# STM32H745_CM7 register map
File version: 2.5
CPU: CM7 r0p1, little endian, MPU, FPU, 4 interrupt priority bits
Registers are 32-bit, read-write, reset 0x0 unless marked. A register's access mark holds for its fields unless they carry their own. Offsets are from the block's base; [hi:lo] are bit positions; {n}, {i} and the like mark numbered series; 'fields as' and 'values as' point back to an identical list.

## BDMA
Base 0x58025400
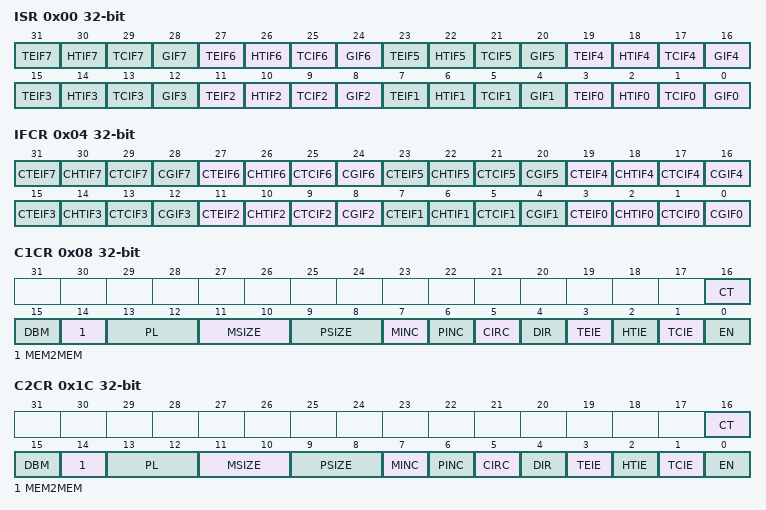
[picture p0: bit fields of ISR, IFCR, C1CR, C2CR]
0x00 ISR ro — DMA interrupt status register
  [4n+3] TEIF{n} (n=0..7) — Channel x transfer error flag (x = 1..8) This bit is set by hardware. It is cleared by software writing 1 to the corresponding bit in the DMA_IFCR register.
  [4n+2] HTIF{n} (n=0..7) — Channel x half transfer flag (x = 1..8) This bit is set by hardware. It is cleared by software writing 1 to the corresponding bit in the DMA_IFCR register.
  [4n+1] TCIF{n} (n=0..7) — Channel x transfer complete flag (x = 1..8) This bit is set by hardware. It is cleared by software writing 1 to the corresponding bit in the DMA_IFCR register.
  [4n] GIF{n} (n=0..7) — Channel x global interrupt flag (x = 1..8) This bit is set by hardware. It is cleared by software writing 1 to the corresponding bit in the DMA_IFCR register.
0x04 IFCR wo — DMA interrupt flag clear register
  [4n+3] CTEIF{n} (n=0..7) — Channel x transfer error clear This bit is set and cleared by software.
  [4n+2] CHTIF{n} (n=0..7) — Channel x half transfer clear This bit is set and cleared by software.
  [4n+1] CTCIF{n} (n=0..7) — Channel x transfer complete clear This bit is set and cleared by software.
  [4n] CGIF{n} (n=0..7) — Channel x global interrupt clear This bit is set and cleared by software.
0x08 C1CR — DMA channel x configuration register
  [16] CT — current target memory of DMA transfer in double-buffer mode This bit is toggled by hardware at the end of each channel transfer in double-buffer mode
  [15] DBM — double-buffer mode This bit must be set only in memory-to-peripheral and peripheral-to-memory transfers
  [14] MEM2MEM — Memory to memory mode This bit is set and cleared by software.
  [13:12] PL — Channel priority level These bits are set and cleared by software.
  [11:10] MSIZE — Memory size These bits are set and cleared by software.
  [9:8] PSIZE — Peripheral size These bits are set and cleared by software.
  [7] MINC — Memory increment mode This bit is set and cleared by software.
  [6] PINC — Peripheral increment mode This bit is set and cleared by software.
  [5] CIRC — Circular mode This bit is set and cleared by software.
  [4] DIR — Data transfer direction This bit is set and cleared by software.
  [3] TEIE — Transfer error interrupt enable This bit is set and cleared by software.
  [2] HTIE — Half transfer interrupt enable This bit is set and cleared by software.
  [1] TCIE — Transfer complete interrupt enable This bit is set and cleared by software.
  [0] EN — Channel enable This bit is set and cleared by software.
0x0C C1NDTR — DMA channel x number of data register
  [15:0] NDT — Number of data to transfer Number of data to be transferred (0 up to 65535). This register can only be written when the channel is disabled. Once the channel is enabled, this register is read-only, indicating the remaining bytes to be transmitted. This register decrements after each DMA transfer. Once the transfer is completed, this register can either stay at zero or be reloaded automatically by the value previously programmed if the channel is configured in auto-reload mode. If this register is zero, no transaction can be served whether the channel is enabled or not.
0x10 C1PAR — This register must not be written when the channel is enabled.
  [31:0] PA — Peripheral address Base address of the peripheral data register from/to which the data will be read/written. When PSIZE is 01 (16-bit), the PA[0] bit is ignored. Access is automatically aligned to a half-word address. When PSIZE is 10 (32-bit), PA[1:0] are ignored. Access is automatically aligned to a word address.
{0x0+0x14*i} C{i}MAR1 (i=1..8) — This register must not be written when the channel is enabled.
  [31:0] MA — Memory address Base address of the memory area from/to which the data will be read/written. When MSIZE is 01 (16-bit), the MA[0] bit is ignored. Access is automatically aligned to a half-word address. When MSIZE is 10 (32-bit), MA[1:0] are ignored. Access is automatically aligned to a word address.
{0x4+0x14*i} C{i}MAR2 (i=1..8) — This register must not be written when the channel is enabled.
  fields as C1MAR1
0x1C C2CR — DMA channel x configuration register
  fields as C1CR
0x20 C2NDTR — DMA channel x number of data register
  fields as C1NDTR
0x24 C2PAR — This register must not be written when the channel is enabled.
  fields as C1PAR
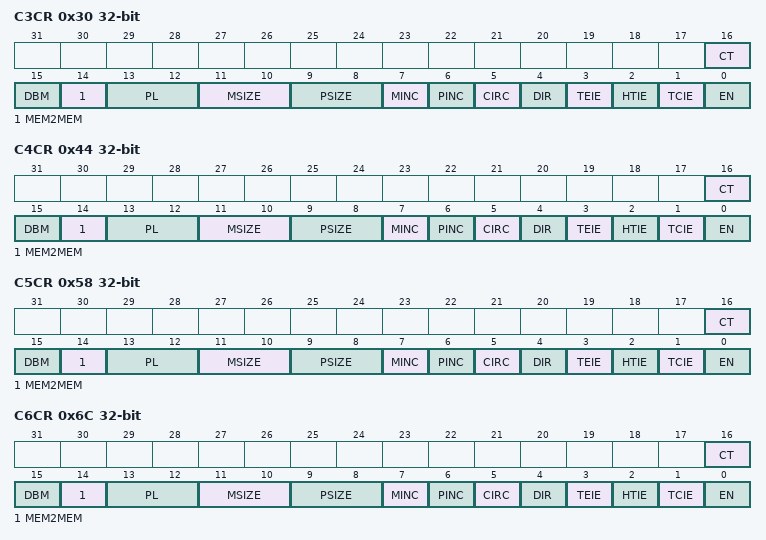
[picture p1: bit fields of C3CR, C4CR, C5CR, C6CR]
0x30 C3CR — DMA channel x configuration register
  fields as C1CR
0x34 C3NDTR — DMA channel x number of data register
  fields as C1NDTR
0x38 C3PAR — This register must not be written when the channel is enabled.
  fields as C1PAR
0x44 C4CR — DMA channel x configuration register
  fields as C1CR
0x48 C4NDTR — DMA channel x number of data register
  fields as C1NDTR
0x4C C4PAR — This register must not be written when the channel is enabled.
  fields as C1PAR
0x58 C5CR — DMA channel x configuration register
  fields as C1CR
0x5C C5NDTR — DMA channel x number of data register
  fields as C1NDTR
0x60 C5PAR — This register must not be written when the channel is enabled.
  fields as C1PAR
0x6C C6CR — DMA channel x configuration register
  fields as C1CR
0x70 C6NDTR — DMA channel x number of data register
  fields as C1NDTR
0x74 C6PAR — This register must not be written when the channel is enabled.
  fields as C1PAR
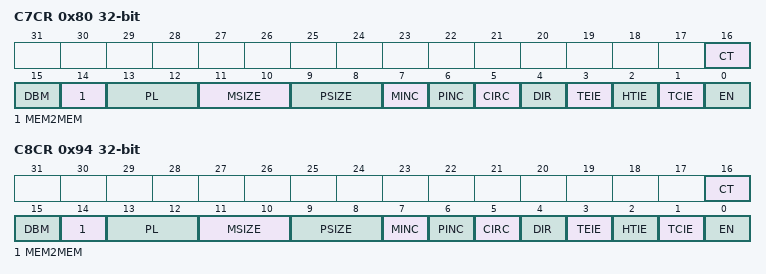
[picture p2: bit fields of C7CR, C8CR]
0x80 C7CR — DMA channel x configuration register
  fields as C1CR
0x84 C7NDTR — DMA channel x number of data register
  fields as C1NDTR
0x88 C7PAR — This register must not be written when the channel is enabled.
  fields as C1PAR
0x94 C8CR — DMA channel x configuration register
  fields as C1CR
0x98 C8NDTR — DMA channel x number of data register
  fields as C1NDTR
0x9C C8PAR — This register must not be written when the channel is enabled.
  fields as C1PAR

## Notices in the file
Copyright (c) 2025 STMicroelectronics.
SPDX-License-Identifier: Apache-2.0
Licensed under the Apache License, Version 2.0 (the "License");
you may not use this file except in compliance with the License.
You may obtain a copy of the License at
http://www.apache.org/licenses/LICENSE-2.0
Unless required by applicable law or agreed to in writing, software
distributed under the License is distributed on an "AS IS" BASIS,
WITHOUT WARRANTIES OR CONDITIONS OF ANY KIND, either express or implied.
See the License for the specific language governing permissions and
limitations under the License.
